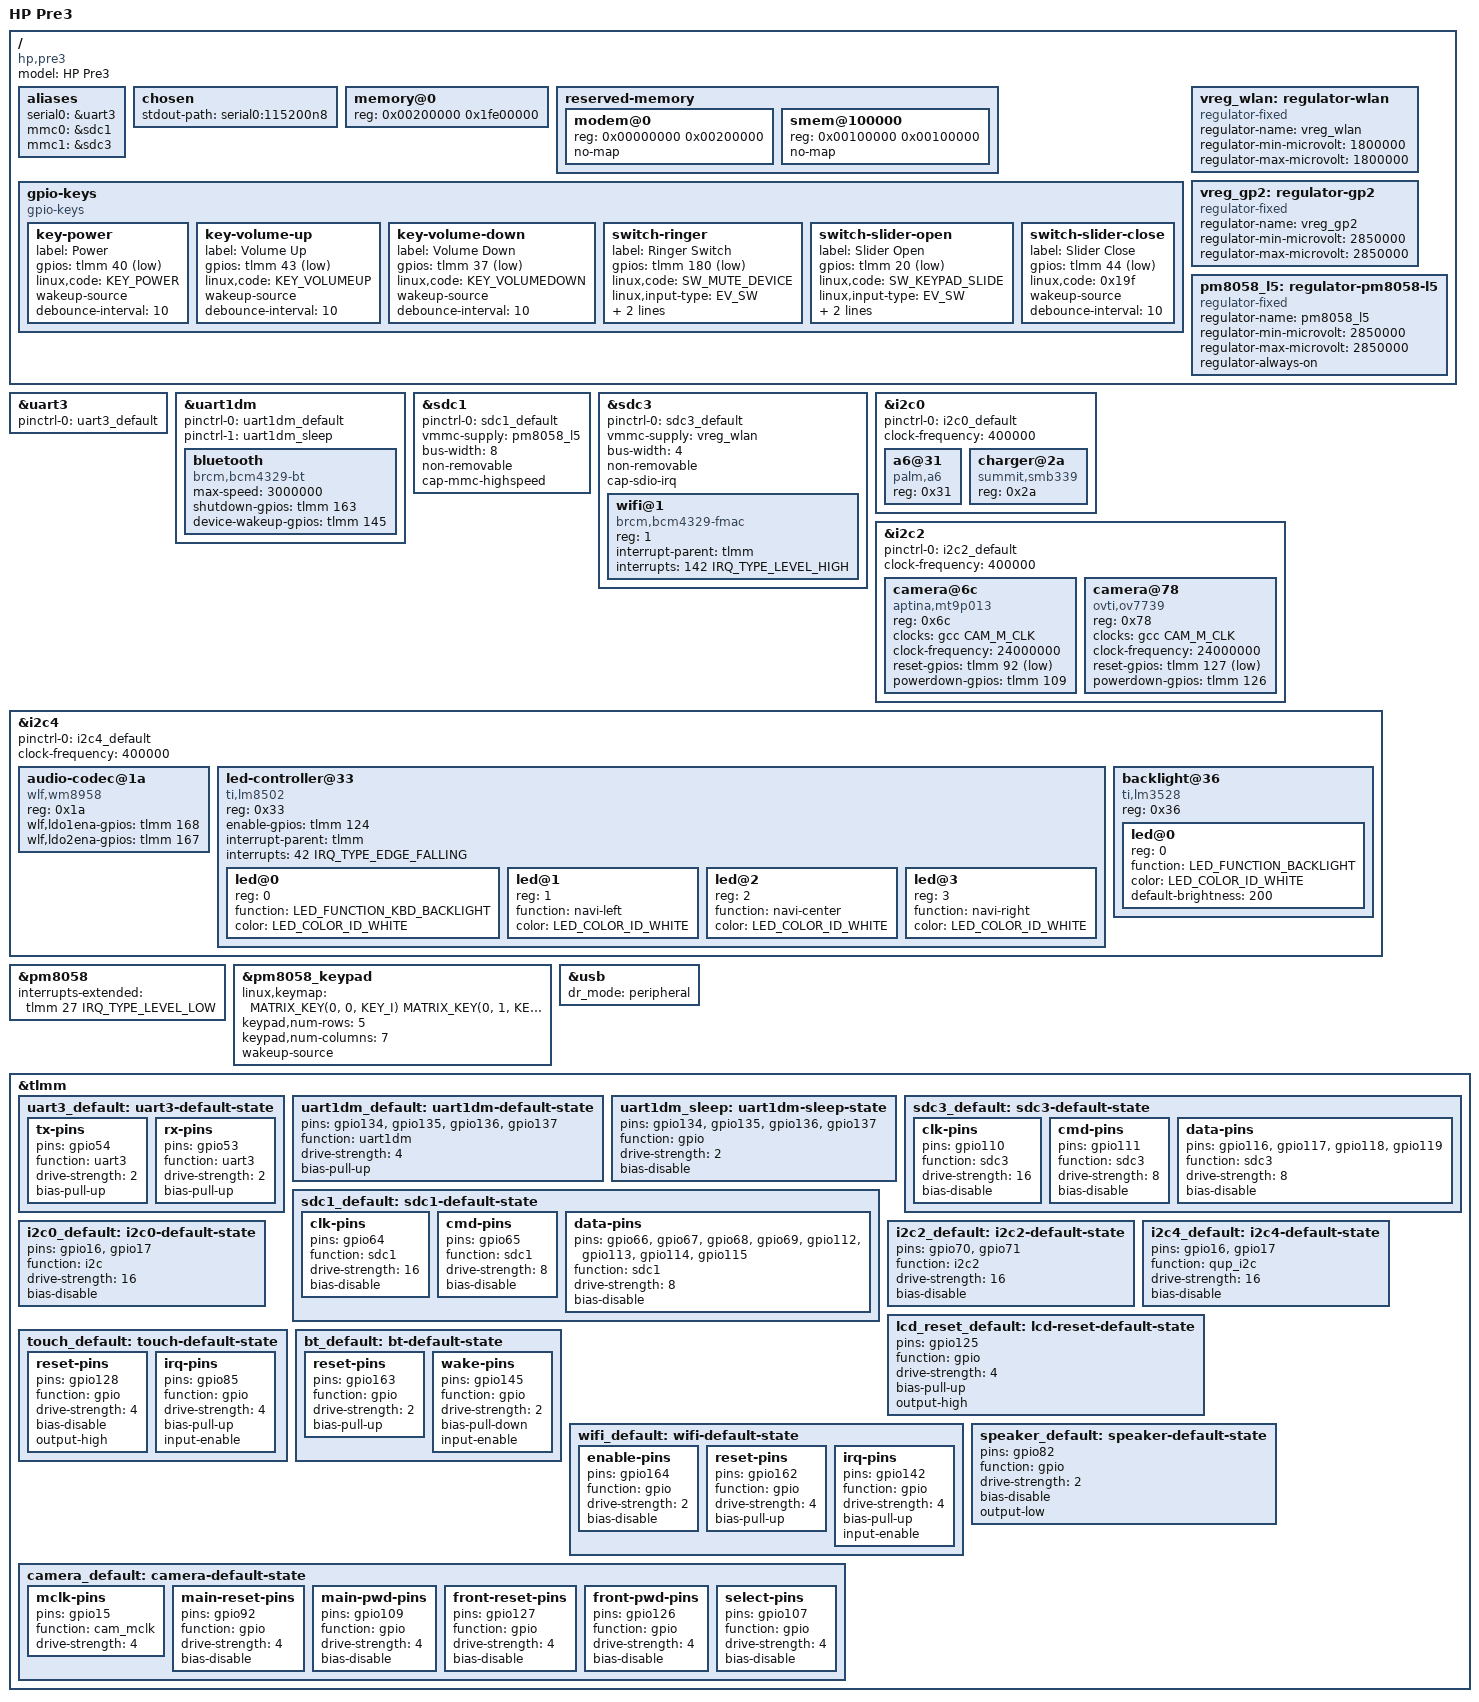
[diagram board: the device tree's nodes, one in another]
// SPDX-License-Identifier: GPL-2.0-only
/*
 * Copyright (c) 2024, Linux community
 *
 * Device Tree Source for HP Pre3
 * Codenames: mantaray (device), rib (board)
 */

/dts-v1/;

#include "qcom-msm7x30.dtsi"
#include "pm8058.dtsi"
#include <dt-bindings/input/input.h>
#include <dt-bindings/leds/common.h>

/ {
	model = "HP Pre3";
	compatible = "hp,pre3", "qcom,msm7x30";

	aliases {
		serial0 = &uart3;
		mmc0 = &sdc1;
		mmc1 = &sdc3;
	};

	chosen {
		stdout-path = "serial0:115200n8";
	};

	memory@0 {
		device_type = "memory";
		/* 512MB RAM, first 2MB reserved for modem */
		reg = <0x00200000 0x1fe00000>;
	};

	reserved-memory {
		#address-cells = <1>;
		#size-cells = <1>;
		ranges;

		/* Modem/AMSS firmware */
		modem@0 {
			reg = <0x00000000 0x00200000>;
			no-map;
		};

		/* Shared memory with modem */
		smem@100000 {
			reg = <0x00100000 0x00100000>;
			no-map;
		};
	};

	gpio-keys {
		compatible = "gpio-keys";

		key-power {
			label = "Power";
			gpios = <&tlmm 40 GPIO_ACTIVE_LOW>;
			linux,code = <KEY_POWER>;
			wakeup-source;
			debounce-interval = <10>;
		};

		key-volume-up {
			label = "Volume Up";
			gpios = <&tlmm 43 GPIO_ACTIVE_LOW>;
			linux,code = <KEY_VOLUMEUP>;
			wakeup-source;
			debounce-interval = <10>;
		};

		key-volume-down {
			label = "Volume Down";
			gpios = <&tlmm 37 GPIO_ACTIVE_LOW>;
			linux,code = <KEY_VOLUMEDOWN>;
			wakeup-source;
			debounce-interval = <10>;
		};

		switch-ringer {
			label = "Ringer Switch";
			gpios = <&tlmm 180 GPIO_ACTIVE_LOW>;
			linux,code = <SW_MUTE_DEVICE>;
			linux,input-type = <EV_SW>;
			wakeup-source;
			debounce-interval = <100>;
		};

		switch-slider-open {
			label = "Slider Open";
			gpios = <&tlmm 20 GPIO_ACTIVE_LOW>;
			linux,code = <SW_KEYPAD_SLIDE>;
			linux,input-type = <EV_SW>;
			wakeup-source;
			debounce-interval = <10>;
		};

		switch-slider-close {
			label = "Slider Close";
			gpios = <&tlmm 44 GPIO_ACTIVE_LOW>;
			/* Custom code for slider close detection */
			linux,code = <0x19f>;
			wakeup-source;
			debounce-interval = <10>;
		};
	};

	/*
	 * Regulators controlled via PCOM RPC
	 * These are virtual regulators managed by the modem
	 */
	vreg_wlan: regulator-wlan {
		compatible = "regulator-fixed";
		regulator-name = "vreg_wlan";
		regulator-min-microvolt = <1800000>;
		regulator-max-microvolt = <1800000>;
		/* Controlled via proc_comm */
	};

	vreg_gp2: regulator-gp2 {
		compatible = "regulator-fixed";
		regulator-name = "vreg_gp2";
		regulator-min-microvolt = <2850000>;
		regulator-max-microvolt = <2850000>;
	};

	/*
	 * PM8058 LDO5 - eMMC power (2.85V)
	 * TODO: Replace with proper PCOM-based regulator driver
	 */
	pm8058_l5: regulator-pm8058-l5 {
		compatible = "regulator-fixed";
		regulator-name = "pm8058_l5";
		regulator-min-microvolt = <2850000>;
		regulator-max-microvolt = <2850000>;
		regulator-always-on;
	};
};

/* Debug UART */
&uart3 {
	status = "okay";

	pinctrl-names = "default";
	pinctrl-0 = <&uart3_default>;
};

/* Bluetooth HCI UART */
&uart1dm {
	status = "okay";

	pinctrl-names = "default", "sleep";
	pinctrl-0 = <&uart1dm_default>;
	pinctrl-1 = <&uart1dm_sleep>;

	bluetooth {
		compatible = "brcm,bcm4329-bt";
		max-speed = <3000000>;
		shutdown-gpios = <&tlmm 163 GPIO_ACTIVE_HIGH>;
		device-wakeup-gpios = <&tlmm 145 GPIO_ACTIVE_HIGH>;
	};
};

/* eMMC */
&sdc1 {
	status = "okay";

	pinctrl-names = "default";
	pinctrl-0 = <&sdc1_default>;

	vmmc-supply = <&pm8058_l5>;
	bus-width = <8>;
	non-removable;
	cap-mmc-highspeed;
};

/* WiFi SDIO */
&sdc3 {
	status = "okay";

	pinctrl-names = "default";
	pinctrl-0 = <&sdc3_default>;

	vmmc-supply = <&vreg_wlan>;
	bus-width = <4>;
	non-removable;
	cap-sdio-irq;

	#address-cells = <1>;
	#size-cells = <0>;

	wifi@1 {
		compatible = "brcm,bcm4329-fmac";
		reg = <1>;
		interrupt-parent = <&tlmm>;
		interrupts = <142 IRQ_TYPE_LEVEL_HIGH>;
		interrupt-names = "host-wake";
	};
};

/* Main I2C bus */
&i2c0 {
	status = "okay";

	pinctrl-names = "default";
	pinctrl-0 = <&i2c0_default>;

	clock-frequency = <400000>;

	/* A6 Battery MCU */
	a6@31 {
		compatible = "palm,a6";
		reg = <0x31>;
		/* Palm proprietary battery management */
	};

	/* SMB339 Charger */
	charger@2a {
		compatible = "summit,smb339";
		reg = <0x2a>;
	};
};

/* Camera I2C bus */
&i2c2 {
	status = "okay";

	pinctrl-names = "default";
	pinctrl-0 = <&i2c2_default>;

	clock-frequency = <400000>;

	/* Main camera - 5MP */
	camera@6c {
		compatible = "aptina,mt9p013";
		reg = <0x6c>;

		clocks = <&gcc CAM_M_CLK>;
		clock-names = "mclk";
		clock-frequency = <24000000>;

		reset-gpios = <&tlmm 92 GPIO_ACTIVE_LOW>;
		powerdown-gpios = <&tlmm 109 GPIO_ACTIVE_HIGH>;
	};

	/* Front camera - VGA */
	camera@78 {
		compatible = "ovti,ov7739";
		reg = <0x78>;

		clocks = <&gcc CAM_M_CLK>;
		clock-names = "mclk";
		clock-frequency = <24000000>;

		reset-gpios = <&tlmm 127 GPIO_ACTIVE_LOW>;
		powerdown-gpios = <&tlmm 126 GPIO_ACTIVE_HIGH>;
	};
};

/* Peripheral I2C bus (QUP) */
&i2c4 {
	status = "okay";

	pinctrl-names = "default";
	pinctrl-0 = <&i2c4_default>;

	clock-frequency = <400000>;

	/* WM8958 Audio Codec */
	audio-codec@1a {
		compatible = "wlf,wm8958";
		reg = <0x1a>;

		wlf,ldo1ena-gpios = <&tlmm 168 GPIO_ACTIVE_HIGH>;
		wlf,ldo2ena-gpios = <&tlmm 167 GPIO_ACTIVE_HIGH>;

		#sound-dai-cells = <0>;
	};

	/* LM8502 LED Controller */
	led-controller@33 {
		compatible = "ti,lm8502";
		reg = <0x33>;

		enable-gpios = <&tlmm 124 GPIO_ACTIVE_HIGH>;
		interrupt-parent = <&tlmm>;
		interrupts = <42 IRQ_TYPE_EDGE_FALLING>;

		#address-cells = <1>;
		#size-cells = <0>;

		led@0 {
			reg = <0>;
			function = LED_FUNCTION_KBD_BACKLIGHT;
			color = <LED_COLOR_ID_WHITE>;
		};

		led@1 {
			reg = <1>;
			function = "navi-left";
			color = <LED_COLOR_ID_WHITE>;
		};

		led@2 {
			reg = <2>;
			function = "navi-center";
			color = <LED_COLOR_ID_WHITE>;
		};

		led@3 {
			reg = <3>;
			function = "navi-right";
			color = <LED_COLOR_ID_WHITE>;
		};
	};

	/* LM3528 LCD Backlight */
	backlight@36 {
		compatible = "ti,lm3528";
		reg = <0x36>;

		#address-cells = <1>;
		#size-cells = <0>;

		led@0 {
			reg = <0>;
			function = LED_FUNCTION_BACKLIGHT;
			color = <LED_COLOR_ID_WHITE>;
			default-brightness = <200>;
		};
	};
};

/* PM8058 PMIC configuration */
&pm8058 {
	interrupts-extended = <&tlmm 27 IRQ_TYPE_LEVEL_LOW>;
};

/* Hardware keyboard on PMIC */
&pm8058_keypad {
	status = "okay";

	linux,keymap = <
		/* Row 0 */
		MATRIX_KEY(0, 0, KEY_I)
		MATRIX_KEY(0, 1, KEY_O)
		MATRIX_KEY(0, 2, KEY_P)
		MATRIX_KEY(0, 3, KEY_K)
		MATRIX_KEY(0, 4, KEY_L)
		MATRIX_KEY(0, 5, KEY_BACKSPACE)
		MATRIX_KEY(0, 6, KEY_ENTER)

		/* Row 1 */
		MATRIX_KEY(1, 0, KEY_RIGHTALT)
		MATRIX_KEY(1, 1, KEY_0)
		MATRIX_KEY(1, 2, KEY_SPACE)
		MATRIX_KEY(1, 3, KEY_DOT)
		MATRIX_KEY(1, 4, KEY_LEFTALT)
		MATRIX_KEY(1, 5, KEY_M)
		MATRIX_KEY(1, 6, KEY_COMMA)

		/* Row 2 */
		MATRIX_KEY(2, 0, KEY_LEFTSHIFT)
		MATRIX_KEY(2, 1, KEY_Z)
		MATRIX_KEY(2, 2, KEY_X)
		MATRIX_KEY(2, 3, KEY_C)
		MATRIX_KEY(2, 4, KEY_V)
		MATRIX_KEY(2, 5, KEY_B)
		MATRIX_KEY(2, 6, KEY_N)

		/* Row 3 */
		MATRIX_KEY(3, 0, KEY_A)
		MATRIX_KEY(3, 1, KEY_S)
		MATRIX_KEY(3, 2, KEY_D)
		MATRIX_KEY(3, 3, KEY_F)
		MATRIX_KEY(3, 4, KEY_G)
		MATRIX_KEY(3, 5, KEY_H)
		MATRIX_KEY(3, 6, KEY_J)

		/* Row 4 */
		MATRIX_KEY(4, 0, KEY_Q)
		MATRIX_KEY(4, 1, KEY_W)
		MATRIX_KEY(4, 2, KEY_E)
		MATRIX_KEY(4, 3, KEY_R)
		MATRIX_KEY(4, 4, KEY_T)
		MATRIX_KEY(4, 5, KEY_Y)
		MATRIX_KEY(4, 6, KEY_U)
	>;

	keypad,num-rows = <5>;
	keypad,num-columns = <7>;
	wakeup-source;
};

/* USB */
&usb {
	status = "okay";
	dr_mode = "peripheral";
};

/* Pinctrl definitions */
&tlmm {
	uart3_default: uart3-default-state {
		tx-pins {
			pins = "gpio54";
			function = "uart3";
			drive-strength = <2>;
			bias-pull-up;
		};

		rx-pins {
			pins = "gpio53";
			function = "uart3";
			drive-strength = <2>;
			bias-pull-up;
		};
	};

	uart1dm_default: uart1dm-default-state {
		pins = "gpio134", "gpio135", "gpio136", "gpio137";
		function = "uart1dm";
		drive-strength = <4>;
		bias-pull-up;
	};

	uart1dm_sleep: uart1dm-sleep-state {
		pins = "gpio134", "gpio135", "gpio136", "gpio137";
		function = "gpio";
		drive-strength = <2>;
		bias-disable;
	};

	sdc1_default: sdc1-default-state {
		clk-pins {
			pins = "gpio64";
			function = "sdc1";
			drive-strength = <16>;
			bias-disable;
		};

		cmd-pins {
			pins = "gpio65";
			function = "sdc1";
			drive-strength = <8>;
			bias-disable;
		};

		data-pins {
			pins = "gpio66", "gpio67", "gpio68", "gpio69",
			       "gpio112", "gpio113", "gpio114", "gpio115";
			function = "sdc1";
			drive-strength = <8>;
			bias-disable;
		};
	};

	sdc3_default: sdc3-default-state {
		clk-pins {
			pins = "gpio110";
			function = "sdc3";
			drive-strength = <16>;
			bias-disable;
		};

		cmd-pins {
			pins = "gpio111";
			function = "sdc3";
			drive-strength = <8>;
			bias-disable;
		};

		data-pins {
			pins = "gpio116", "gpio117", "gpio118", "gpio119";
			function = "sdc3";
			drive-strength = <8>;
			bias-disable;
		};
	};

	i2c0_default: i2c0-default-state {
		pins = "gpio16", "gpio17";
		function = "i2c";
		drive-strength = <16>;
		bias-disable;
	};

	i2c2_default: i2c2-default-state {
		pins = "gpio70", "gpio71";
		function = "i2c2";
		drive-strength = <16>;
		bias-disable;
	};

	i2c4_default: i2c4-default-state {
		/* QUP I2C uses GSBI pins */
		pins = "gpio16", "gpio17";
		function = "qup_i2c";
		drive-strength = <16>;
		bias-disable;
	};

	lcd_reset_default: lcd-reset-default-state {
		pins = "gpio125";
		function = "gpio";
		drive-strength = <4>;
		bias-pull-up;
		output-high;
	};

	touch_default: touch-default-state {
		reset-pins {
			pins = "gpio128";
			function = "gpio";
			drive-strength = <4>;
			bias-disable;
			output-high;
		};

		irq-pins {
			pins = "gpio85";
			function = "gpio";
			drive-strength = <4>;
			bias-pull-up;
			input-enable;
		};
	};

	bt_default: bt-default-state {
		reset-pins {
			pins = "gpio163";
			function = "gpio";
			drive-strength = <2>;
			bias-pull-up;
		};

		wake-pins {
			pins = "gpio145";
			function = "gpio";
			drive-strength = <2>;
			bias-pull-down;
			input-enable;
		};
	};

	wifi_default: wifi-default-state {
		enable-pins {
			pins = "gpio164";
			function = "gpio";
			drive-strength = <2>;
			bias-disable;
		};

		reset-pins {
			pins = "gpio162";
			function = "gpio";
			drive-strength = <4>;
			bias-pull-up;
		};

		irq-pins {
			pins = "gpio142";
			function = "gpio";
			drive-strength = <4>;
			bias-pull-up;
			input-enable;
		};
	};

	speaker_default: speaker-default-state {
		pins = "gpio82";
		function = "gpio";
		drive-strength = <2>;
		bias-disable;
		output-low;
	};

	camera_default: camera-default-state {
		mclk-pins {
			pins = "gpio15";
			function = "cam_mclk";
			drive-strength = <4>;
		};

		main-reset-pins {
			pins = "gpio92";
			function = "gpio";
			drive-strength = <4>;
			bias-disable;
		};

		main-pwd-pins {
			pins = "gpio109";
			function = "gpio";
			drive-strength = <4>;
			bias-disable;
		};

		front-reset-pins {
			pins = "gpio127";
			function = "gpio";
			drive-strength = <4>;
			bias-disable;
		};

		front-pwd-pins {
			pins = "gpio126";
			function = "gpio";
			drive-strength = <4>;
			bias-disable;
		};

		select-pins {
			pins = "gpio107";
			function = "gpio";
			drive-strength = <4>;
			bias-disable;
		};
	};
};
